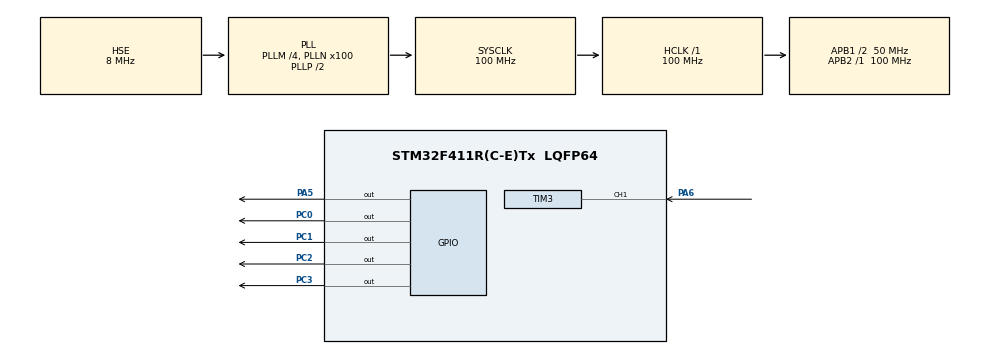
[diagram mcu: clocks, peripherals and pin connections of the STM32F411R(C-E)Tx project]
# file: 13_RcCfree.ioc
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Mcu.Family=STM32F4
Mcu.Name=STM32F411R(C-E)Tx
Mcu.Package=LQFP64
NVIC.PriorityGroup=NVIC_PRIORITYGROUP_4
NVIC.TIM3_IRQn=true\:0\:0\:false\:false\:true\:true\:true\:true
PA13.Mode=Serial_Wire
PA13.Signal=SYS_JTMS-SWDIO
PA14.Mode=Serial_Wire
PA14.Signal=SYS_JTCK-SWCLK
PA5.Signal=GPIO_Output
PA6.Signal=S_TIM3_CH1
PC0.Signal=GPIO_Output
PC1.Signal=GPIO_Output
PC2.Signal=GPIO_Output
PC3.Signal=GPIO_Output
PH0\ -\ OSC_IN.Mode=HSE-External-Oscillator
PH0\ -\ OSC_IN.Signal=RCC_OSC_IN
PH1\ -\ OSC_OUT.Mode=HSE-External-Oscillator
PH1\ -\ OSC_OUT.Signal=RCC_OSC_OUT
ProjectManager.HeapSize=0x200
ProjectManager.StackSize=0x400
ProjectManager.TargetToolchain=STM32CubeIDE
RCC.48MHZClocksFreq_Value=50000000
RCC.AHBFreq_Value=100000000
RCC.APB1CLKDivider=RCC_HCLK_DIV2
RCC.APB1Freq_Value=50000000
RCC.APB1TimFreq_Value=100000000
RCC.APB2Freq_Value=100000000
RCC.APB2TimFreq_Value=100000000
RCC.CortexFreq_Value=100000000
RCC.HCLKFreq_Value=100000000
RCC.HSE_VALUE=8000000
RCC.HSI_VALUE=16000000
RCC.LSE_VALUE=32768
RCC.PLLM=4
RCC.PLLN=100
RCC.PLLSourceVirtual=RCC_PLLSOURCE_HSE
RCC.SYSCLKFreq_VALUE=100000000
RCC.SYSCLKSource=RCC_SYSCLKSOURCE_PLLCLK
RCC.VCOOutputFreq_Value=200000000
SH.S_TIM3_CH1.0=TIM3_CH1,Input_Capture1_from_TI1
TIM10.Prescaler=100-1
TIM3.Channel-Input_Capture1_from_TI1=TIM_CHANNEL_1
TIM3.Prescaler=100-1
VP_TIM10_VS_ClockSourceINT.Mode=Enable_Timer
VP_TIM3_VS_ClockSourceINT.Mode=Internal
board=custom

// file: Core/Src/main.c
/* USER CODE BEGIN Header */
/**
  ******************************************************************************
  * @file           : main.c
  * @brief          : Main program body
  ******************************************************************************
  * @attention
  *
  * Copyright (c) 2025 STMicroelectronics.
  * All rights reserved.
  *
  ******************************************************************************
  */
/* USER CODE END Header */

#include "main.h"
#include "tim.h"
#include "gpio.h"

#include "ultrasonic.h"
#include "delay_us.h"
#include <stdio.h>      // printf 사용 위해 포함

#define SAFE_DISTANCE 20   // cm

uint32_t front_distance;
uint32_t left_distance;
uint32_t right_distance;

void SystemClock_Config(void);
void AutonomousDrive(void);

/* USER CODE BEGIN 0 */
// 디버깅용 _write() 제거 또는 필요시 SEGGER RTT 등으로 대체 가능
/* USER CODE END 0 */

/* USER CODE BEGIN 1 */
int main(void)
{
    HAL_Init();
    SystemClock_Config();

    MX_GPIO_Init();
    MX_TIM3_Init();
    MX_TIM10_Init();

    HAL_TIM_Base_Start(&htim10);              // delay_us용 타이머
    HAL_TIM_IC_Start_IT(&htim3, TIM_CHANNEL_1); // 초음파 캡처 인터럽트

    while (1)
    {
        AutonomousDrive();
    }
}

/* AutonomousDrive 함수 정의 - main 밖으로 이동 */
void AutonomousDrive(void)
{
    // 거리 측정
    HCSR04_TRIGGER_FRONT();
    HAL_Delay(50);
    front_distance = distance;

    HCSR04_TRIGGER_LEFT();
    HAL_Delay(50);
    left_distance = distance;

    HCSR04_TRIGGER_RIGHT();
    HAL_Delay(50);
    right_distance = distance;

    printf("Front:%ld cm, Left:%ld cm, Right:%ld cm\r\n",
           front_distance, left_distance, right_distance);

    if(front_distance < SAFE_DISTANCE)
    {
        Car_Stop();
        HAL_Delay(200);

        Car_Backward();
        HAL_Delay(300);

        // 좌우 회피 결정
        if(left_distance > right_distance)
        {
            Car_Left();
        }
        else
        {
            Car_Right();
        }
        HAL_Delay(400);
    }
    else
    {
        Car_Forward();
    }
}

/* System Clock Configuration */
void SystemClock_Config(void)
{
    RCC_OscInitTypeDef RCC_OscInitStruct = {0};
    RCC_ClkInitTypeDef RCC_ClkInitStruct = {0};

    __HAL_RCC_PWR_CLK_ENABLE();
    __HAL_PWR_VOLTAGESCALING_CONFIG(PWR_REGULATOR_VOLTAGE_SCALE1);

    RCC_OscInitStruct.OscillatorType = RCC_OSCILLATORTYPE_HSE;
    RCC_OscInitStruct.HSEState = RCC_HSE_ON;
    RCC_OscInitStruct.PLL.PLLState = RCC_PLL_ON;
    RCC_OscInitStruct.PLL.PLLSource = RCC_PLLSOURCE_HSE;
    RCC_OscInitStruct.PLL.PLLM = 4;
    RCC_OscInitStruct.PLL.PLLN = 100;
    RCC_OscInitStruct.PLL.PLLP = RCC_PLLP_DIV2;
    RCC_OscInitStruct.PLL.PLLQ = 4;
    if(HAL_RCC_OscConfig(&RCC_OscInitStruct) != HAL_OK) { Error_Handler(); }

    RCC_ClkInitStruct.ClockType = RCC_CLOCKTYPE_HCLK|RCC_CLOCKTYPE_SYSCLK
                                |RCC_CLOCKTYPE_PCLK1|RCC_CLOCKTYPE_PCLK2;
    RCC_ClkInitStruct.SYSCLKSource = RCC_SYSCLKSOURCE_PLLCLK;
    RCC_ClkInitStruct.AHBCLKDivider = RCC_SYSCLK_DIV1;
    RCC_ClkInitStruct.APB1CLKDivider = RCC_HCLK_DIV2;
    RCC_ClkInitStruct.APB2CLKDivider = RCC_HCLK_DIV1;
    if(HAL_RCC_ClockConfig(&RCC_ClkInitStruct, FLASH_LATENCY_3) != HAL_OK) { Error_Handler(); }
}

/* Error Handler */
void Error_Handler(void)
{
    __disable_irq();
    while(1) {}
}
